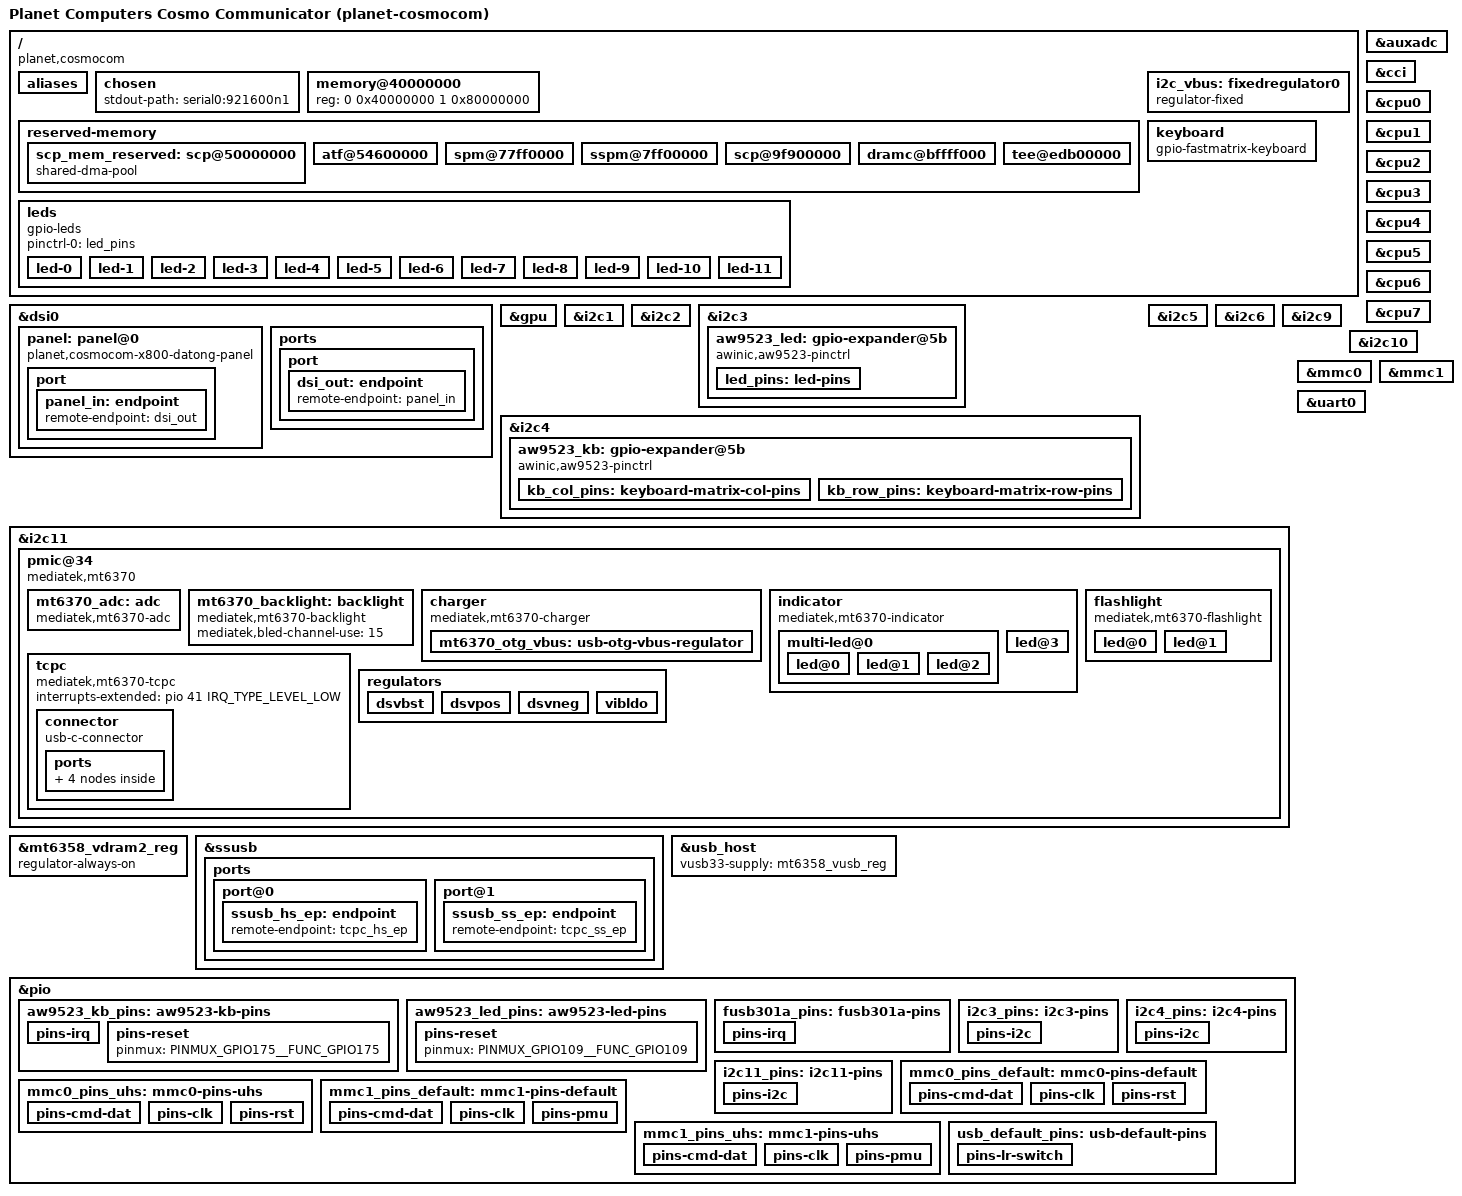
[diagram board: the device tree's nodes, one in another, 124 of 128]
// SPDX-License-Identifier: GPL-2.0-only
/dts-v1/;
#include <dt-bindings/gpio/gpio.h>
#include <dt-bindings/iio/adc/mediatek,mt6370_adc.h>
#include <dt-bindings/input/input.h>
#include <dt-bindings/interrupt-controller/irq.h>
#include <dt-bindings/leds/common.h>
#include <dt-bindings/usb/pd.h>
#include "mt6771.dtsi"
#include "mt6358.dtsi"

/ {
	model = "Planet Computers Cosmo Communicator (planet-cosmocom)";
	compatible = "planet,cosmocom", "mediatek,mt6771";
	chassis-type = "handset";

	aliases {
		serial0 = &uart0;
		mmc0 = &mmc0;
		mmc1 = &mmc1;
	};

	chosen {
		stdout-path = "serial0:921600n1";
	};

	memory@40000000 {
		device_type = "memory";
		reg = <0 0x40000000 1 0x80000000>;
	};

	reserved-memory {
		#address-cells = <2>;
		#size-cells = <2>;
		ranges;

		scp_mem_reserved: scp@50000000 {
                        compatible = "shared-dma-pool";
			reg = <0 0x50000000 0 0x140000>;
			no-map;
		};

		atf@54600000 {
			reg = <0 0x54600000 0 0x040000>;
			no-map;
		};

		spm@77ff0000 {
			reg = <0 0x77ff0000 0 0x010000>;
			no-map;
		};

		sspm@7ff00000 {
			reg = <0 0x7ff00000 0 0x0c0000>;
			no-map;
		};

                scp@9f900000 {
                        reg = <0 0x9f900000 0 0x600000>;
                        no-map;
                };

		dramc@bffff000 {
			reg = <0 0xbffff000 0 0x1000>;
			no-map;
		};

		tee@edb00000 {
			reg = <0 0xedb00000 0 0x02440000>;
			no-map;
		};
	};

	/*
	framebuffer@7df70000 {
		compatible = "simple-framebuffer";
		reg = <0 0x7df70000 0 0x1f90000>;
		format = "a8r8g8b8";
		width = <1080>;
		stride = <4352>;
		height = <2160>;
	};
	*/

	i2c_vbus: fixedregulator0 {
		compatible = "regulator-fixed";
		regulator-name = "i2c-vbus";
		regulator-min-microvolt = <1800000>;
		regulator-max-microvolt = <1800000>;
		regulator-boot-on;
	};

	leds {
		pinctrl-names = "default";
		pinctrl-0 = <&led_pins>;
		compatible = "gpio-leds";

		led-0 {
			gpios = <&aw9523_led 0 GPIO_ACTIVE_LOW>;
			function = LED_FUNCTION_CAPSLOCK;
			color = <LED_COLOR_ID_RED>;
		};

		led-1 {
			gpios = <&aw9523_led 1 GPIO_ACTIVE_LOW>;
			function = LED_FUNCTION_NUMLOCK;
			color = <LED_COLOR_ID_GREEN>;
		};

		led-2 {
			gpios = <&aw9523_led 2 GPIO_ACTIVE_LOW>;
			function = LED_FUNCTION_SCROLLLOCK;
			color = <LED_COLOR_ID_BLUE>;
		};

		led-3 {
			gpios = <&aw9523_led 3 GPIO_ACTIVE_LOW>;
			function = LED_FUNCTION_STATUS;
			color = <LED_COLOR_ID_RED>;
		};

		led-4 {
			gpios = <&aw9523_led 4 GPIO_ACTIVE_LOW>;
			function = LED_FUNCTION_STATUS;
			color = <LED_COLOR_ID_GREEN>;
		};

		led-5 {
			gpios = <&aw9523_led 5 GPIO_ACTIVE_LOW>;
			function = LED_FUNCTION_STATUS;
			color = <LED_COLOR_ID_BLUE>;
		};

		led-6 {
			gpios = <&aw9523_led 7 GPIO_ACTIVE_LOW>;
			function = LED_FUNCTION_INDICATOR;
			color = <LED_COLOR_ID_RED>;
		};

		led-7 {
			gpios = <&aw9523_led 8 GPIO_ACTIVE_LOW>;
			function = LED_FUNCTION_INDICATOR;
			color = <LED_COLOR_ID_GREEN>;
		};

		led-8 {
			gpios = <&aw9523_led 9 GPIO_ACTIVE_LOW>;
			function = LED_FUNCTION_INDICATOR;
			color = <LED_COLOR_ID_BLUE>;
		};

		led-9 {
			gpios = <&aw9523_led 11 GPIO_ACTIVE_LOW>;
			function = LED_FUNCTION_INDICATOR;
			color = <LED_COLOR_ID_RED>;
		};

		led-10 {
			gpios = <&aw9523_led 12 GPIO_ACTIVE_LOW>;
			function = LED_FUNCTION_INDICATOR;
			color = <LED_COLOR_ID_GREEN>;
		};

		led-11 {
			gpios = <&aw9523_led 13 GPIO_ACTIVE_LOW>;
			function = LED_FUNCTION_INDICATOR;
			color = <LED_COLOR_ID_BLUE>;
		};
	};

	keyboard {
		pinctrl-names = "default";
		pinctrl-0 = <&kb_col_pins>, <&kb_row_pins>;
		compatible = "gpio-fastmatrix-keyboard";
		autorescan-ms = <5>;
		debounce-delay-ms = <2>;
		col-scan-delay-us = <1000>;

		row-gpios = <&aw9523_kb 0 GPIO_ACTIVE_LOW>,
			    <&aw9523_kb 1 GPIO_ACTIVE_LOW>,
			    <&aw9523_kb 2 GPIO_ACTIVE_LOW>,
			    <&aw9523_kb 3 GPIO_ACTIVE_LOW>,
			    <&aw9523_kb 4 GPIO_ACTIVE_LOW>,
			    <&aw9523_kb 5 GPIO_ACTIVE_LOW>,
			    <&aw9523_kb 6 GPIO_ACTIVE_LOW>,
			    <&aw9523_kb 7 GPIO_ACTIVE_LOW>;

		col-gpios = <&aw9523_kb 8 GPIO_ACTIVE_LOW>,
			    <&aw9523_kb 9 GPIO_ACTIVE_LOW>,
			    <&aw9523_kb 10 GPIO_ACTIVE_LOW>,
			    <&aw9523_kb 11 GPIO_ACTIVE_LOW>,
			    <&aw9523_kb 12 GPIO_ACTIVE_LOW>,
			    <&aw9523_kb 13 GPIO_ACTIVE_LOW>,
			    <&aw9523_kb 14 GPIO_ACTIVE_LOW>;

		linux,keymap = <
			MATRIX_KEY(0, 0, KEY_1)
			MATRIX_KEY(1, 0, KEY_U)
			MATRIX_KEY(2, 0, KEY_S)
			MATRIX_KEY(3, 0, KEY_Z)
			MATRIX_KEY(4, 0, KEY_COMMA)
			MATRIX_KEY(5, 0, KEY_APOSTROPHE)
			MATRIX_KEY(6, 0, KEY_8)
			MATRIX_KEY(7, 0, KEY_J)

			MATRIX_KEY(0, 1, KEY_2)
			MATRIX_KEY(1, 1, KEY_W)
			MATRIX_KEY(2, 1, KEY_D)
			MATRIX_KEY(3, 1, KEY_C)
			MATRIX_KEY(4, 1, KEY_LEFTALT)
			MATRIX_KEY(5, 1, KEY_LEFT)
			MATRIX_KEY(6, 1, KEY_9)
			MATRIX_KEY(7, 1, KEY_K)

			MATRIX_KEY(0, 2, KEY_3)
			MATRIX_KEY(1, 2, KEY_Y)
			MATRIX_KEY(2, 2, KEY_TAB)
			MATRIX_KEY(3, 2, KEY_N)
			MATRIX_KEY(4, 2, KEY_M)
			MATRIX_KEY(5, 2, KEY_DOWN)
			MATRIX_KEY(6, 2, KEY_BACKSPACE)
			MATRIX_KEY(7, 2, KEY_I)

			MATRIX_KEY(0, 3, KEY_4)
			MATRIX_KEY(1, 3, KEY_T)
			MATRIX_KEY(2, 3, KEY_F)
			MATRIX_KEY(3, 3, KEY_X)
			MATRIX_KEY(4, 3, KEY_LEFTMETA)
			MATRIX_KEY(5, 3, KEY_RIGHTSHIFT)
			MATRIX_KEY(6, 3, KEY_P)

			MATRIX_KEY(0, 4, KEY_5)
			MATRIX_KEY(1, 4, KEY_E)
			MATRIX_KEY(2, 4, KEY_G)
			MATRIX_KEY(3, 4, KEY_V)
			MATRIX_KEY(4, 4, KEY_SPACE)
			MATRIX_KEY(5, 4, KEY_UP)
			MATRIX_KEY(6, 4, KEY_O)

			MATRIX_KEY(0, 5, KEY_6)
			MATRIX_KEY(1, 5, KEY_Q)
			MATRIX_KEY(2, 5, KEY_A)
			MATRIX_KEY(3, 5, KEY_B)
			MATRIX_KEY(4, 5, KEY_DOT)
			MATRIX_KEY(5, 5, KEY_RIGHT)
			MATRIX_KEY(6, 5, KEY_ENTER)

			MATRIX_KEY(0, 6, KEY_7)
			MATRIX_KEY(1, 6, KEY_R)
			MATRIX_KEY(2, 6, KEY_H)
			MATRIX_KEY(3, 6, KEY_LEFTSHIFT)
			MATRIX_KEY(4, 6, KEY_LEFTCTRL)
			MATRIX_KEY(5, 6, KEY_L)
			MATRIX_KEY(6, 6, KEY_0)
		>;
	};
};

&auxadc {
	status = "okay";
};

&cci {
	proc-supply = <&mt6358_vproc12_reg>;
	sram-supply = <&mt6358_vsram_proc12_reg>;
};

&cpu0 {
	proc-supply = <&mt6358_vproc12_reg>;
	sram-supply = <&mt6358_vsram_proc12_reg>;
};

&cpu1 {
	proc-supply = <&mt6358_vproc12_reg>;
	sram-supply = <&mt6358_vsram_proc12_reg>;
};

&cpu2 {
	proc-supply = <&mt6358_vproc12_reg>;
	sram-supply = <&mt6358_vsram_proc12_reg>;
};

&cpu3 {
	proc-supply = <&mt6358_vproc12_reg>;
	sram-supply = <&mt6358_vsram_proc12_reg>;
};

&cpu4 {
	proc-supply = <&mt6358_vproc11_reg>;
	sram-supply = <&mt6358_vsram_proc11_reg>;
};

&cpu5 {
	proc-supply = <&mt6358_vproc11_reg>;
	sram-supply = <&mt6358_vsram_proc11_reg>;
};

&cpu6 {
	proc-supply = <&mt6358_vproc11_reg>;
	sram-supply = <&mt6358_vsram_proc11_reg>;
};

&cpu7 {
	proc-supply = <&mt6358_vproc11_reg>;
	sram-supply = <&mt6358_vsram_proc11_reg>;
};

&dsi0 {
	status = "okay";
	#address-cells = <1>;
	#size-cells = <0>;
	panel: panel@0 {
		compatible = "planet,cosmocom-x800-datong-panel";
		reg = <0>;
		backlight = <&mt6370_backlight>;
		rotation = <270>;
		port {
			panel_in: endpoint {
				remote-endpoint = <&dsi_out>;
			};
		};
	};

	ports {
		port {
			dsi_out: endpoint {
				remote-endpoint = <&panel_in>;
			};
		};
	};
};

&gpu {
	mali-supply = <&mt6358_vgpu_reg>;
	sram-supply = <&mt6358_vsram_gpu_reg>;
};

&i2c1 {
	status = "okay";
};

&i2c2 {
	status = "okay";
};

&i2c3 {
	#address-cells = <1>;
	#size-cells = <0>;
	pinctrl-names = "default";
	pinctrl-0 = <&i2c3_pins>;
	/* hack to get i2c to probe with vbus-supply in tcpc */
	vbus-supply = <&i2c_vbus>;
	clock-frequency = <400000>;
	status = "okay";

#if 0
	tcpc@25 {
		pinctrl-names = "default";
		pinctrl-0 = <&fusb301a_pins>;
		compatible = "fcs,fusb301";
		reg = <0x25>;
		interrupt-parent = <&pio>;
		interrupts = <166 IRQ_TYPE_EDGE_BOTH>;

		connector {
			compatible = "usb-c-connector";
			label = "USB-C";
			vbus-supply = <&mt6370_otg_vbus>;
			data-role = "dual";
			power-role = "dual";
			try-power-role = "sink";
			typec-power-opmode = "default";
			pd-disable;

			ports {
				#address-cells = <1>;
				#size-cells = <0>;

				port@0 {
					tcpc_hs_ep: endpoint {
						remote-endpoint = <&ssusb_hs_ep>;
					};
				};

				port@1 {
					tcpc_ss_ep: endpoint {
						remote-endpoint = <&ssusb_ss_ep>;
					};
				};
			};
		};
	};
#endif

	aw9523_led: gpio-expander@5b {
		pinctrl-names = "default";
		pinctrl-0 = <&aw9523_led_pins>;
		compatible = "awinic,aw9523-pinctrl";
		reg = <0x5b>;
		gpio-controller;
		#gpio-cells = <2>;
		gpio-ranges = <&aw9523_led 0 0 16>;
		interrupt-controller;
		#interrupt-cells = <2>;
		reset-gpios = <&pio 109 GPIO_ACTIVE_HIGH>;

		led_pins: led-pins {
			pins = "gpio0", "gpio1", "gpio2",
			       "gpio3", "gpio4", "gpio5",
			       "gpio6", "gpio7", "gpio8",
			       "gpio9", "gpio10", "gpio11",
			       "gpio12", "gpio13", "gpio14";
			function = "gpio";
			input-disable;
			drive-push-pull;
			output-high;
		};
	};
};

&i2c4 {
	/* use channel 1 instead of 0 */
	reg = <0 0x11008100 0 0xf00>,
	      <0 0x11000100 0 0x80>;
	#address-cells = <1>;
	#size-cells = <0>;
	pinctrl-names = "default";
	pinctrl-0 = <&i2c4_pins>;
	clock-frequency = <400000>;
	status = "okay";

	aw9523_kb: gpio-expander@5b {
		pinctrl-names = "default";
		pinctrl-0 = <&aw9523_kb_pins>;
		compatible = "awinic,aw9523-pinctrl";
		reg = <0x5b>;
		interrupt-parent = <&pio>;
		interrupts = <12 IRQ_TYPE_LEVEL_LOW>;
		gpio-controller;
		#gpio-cells = <2>;
		gpio-ranges = <&aw9523_kb 0 0 16>;
		interrupt-controller;
		#interrupt-cells = <2>;
		reset-gpios = <&pio 175 GPIO_ACTIVE_HIGH>;

		kb_col_pins: keyboard-matrix-col-pins {
			pins = "gpio8", "gpio9", "gpio10", "gpio11",
			       "gpio12", "gpio13", "gpio14";
			function = "gpio";
			input-disable;
			output-low;
		};

		kb_row_pins: keyboard-matrix-row-pins {
			pins = "gpio0", "gpio1", "gpio2", "gpio3",
			       "gpio4", "gpio5", "gpio6", "gpio7";
			function = "gpio";
			bias-pull-up;
			drive-open-drain;
			input-enable;
		};
	};
};

&i2c5 {
	status = "okay";
};

&i2c6 {
	status = "okay";
};

&i2c9 {
	status = "okay";
};

&i2c10 {
	status = "okay";
};

&i2c11 {
	#address-cells = <1>;
	#size-cells = <0>;
	pinctrl-names = "default";
	pinctrl-0 = <&i2c11_pins>;
	/* hack to get i2c to probe with vbus-supply in tcpc */
	vbus-supply = <&i2c_vbus>;
	clock-frequency = <3400000>;
	status = "okay";

	pmic@34 {
		compatible = "mediatek,mt6370";
		reg = <0x34>;
		wakeup-source;
		interrupts-extended = <&pio 10 IRQ_TYPE_LEVEL_LOW>;
		interrupt-controller;
		#interrupt-cells = <1>;

		mt6370_adc: adc {
			compatible = "mediatek,mt6370-adc";
			#io-channel-cells = <1>;
		};

		mt6370_backlight: backlight {
			compatible = "mediatek,mt6370-backlight";
			mediatek,bled-channel-use = /bits/ 8 <15>;
		};

		charger {
			compatible = "mediatek,mt6370-charger";
			interrupts = <68>, <48>, <6>;
			interrupt-names = "uvp_d_evt", "attach_i", "mivr";
			io-channels = <&mt6370_adc MT6370_CHAN_IBUS>;

			mt6370_otg_vbus: usb-otg-vbus-regulator {
				regulator-name = "mt6370-usb-otg-vbus";
				regulator-min-microvolt = <4350000>;
				regulator-max-microvolt = <5800000>;
				regulator-min-microamp = <500000>;
				regulator-max-microamp = <3000000>;
			};
		};

		indicator {
			compatible = "mediatek,mt6370-indicator";
			#address-cells = <1>;
			#size-cells = <0>;

			multi-led@0 {
				reg = <0>;
				function = LED_FUNCTION_INDICATOR;
				color = <LED_COLOR_ID_RGB>;
				led-max-microamp = <24000>;
				#address-cells = <1>;
				#size-cells = <0>;
				led@0 {
					reg = <0>;
					color = <LED_COLOR_ID_RED>;
				};
				led@1 {
					reg = <1>;
					color = <LED_COLOR_ID_GREEN>;
				};
				led@2 {
					reg = <2>;
					color = <LED_COLOR_ID_BLUE>;
				};
			};
			led@3 {
				reg = <3>;
				function = LED_FUNCTION_INDICATOR;
				color = <LED_COLOR_ID_WHITE>;
				led-max-microamp = <6000>;
			};
		};

		flashlight {
			compatible = "mediatek,mt6370-flashlight";
			#address-cells = <1>;
			#size-cells = <0>;
			led@0 {
				reg = <0>;
				led-sources = <0>;
				function = LED_FUNCTION_FLASH;
				color = <LED_COLOR_ID_WHITE>;
				function-enumerator = <1>;
				led-max-microamp = <300000>;
				flash-max-microamp = <1200000>;
				flash-max-timeout-us = <2400000>;
			};
			led@1 {
				reg = <1>;
				led-sources = <1>;
				function = LED_FUNCTION_FLASH;
				color = <LED_COLOR_ID_WHITE>;
				function-enumerator = <2>;
				led-max-microamp = <200000>;
				flash-max-microamp = <1000000>;
				flash-max-timeout-us = <1200000>;
			};
		};

		tcpc {
			compatible = "mediatek,mt6370-tcpc";
			interrupts-extended = <&pio 41 IRQ_TYPE_LEVEL_LOW>;

			connector {
				compatible = "usb-c-connector";
				label = "USB-C";
				vbus-supply = <&mt6370_otg_vbus>;
				data-role = "dual";
				power-role = "dual";
				try-power-role = "sink";
				source-pdos = <PDO_FIXED(5000, 500, PDO_FIXED_DUAL_ROLE | PDO_FIXED_DATA_SWAP)>;
				sink-pdos = <PDO_FIXED(5000, 2000, PDO_FIXED_DUAL_ROLE | PDO_FIXED_DATA_SWAP)>;
				op-sink-microwatt = <10000000>;

				ports {
					#address-cells = <1>;
					#size-cells = <0>;

					port@0 {
						tcpc_hs_ep: endpoint {
							remote-endpoint = <&ssusb_hs_ep>;
						};
					};

					port@1 {
						tcpc_ss_ep: endpoint {
							remote-endpoint = <&ssusb_ss_ep>;
						};
					};
				};
			};
		};

		regulators {
			dsvbst {
				regulator-name = "mt6370-dsv-vbst";
				regulator-min-microvolt = <4000000>;
				regulator-max-microvolt = <6200000>;
			};
			dsvpos {
				regulator-name = "mt6370-dsv-vpos";
				regulator-min-microvolt = <4000000>;
				regulator-max-microvolt = <6000000>;
				regulator-always-on;
			};
			dsvneg {
				regulator-name = "mt6370-dsv-vneg";
				regulator-min-microvolt = <4000000>;
				regulator-max-microvolt = <6000000>;
				regulator-always-on;
			};
			vibldo {
				regulator-name = "mt6370-vib-ldo";
				regulator-min-microvolt = <1600000>;
				regulator-max-microvolt = <4000000>;
			};
		};
	};
};

&mmc0 {
	status = "okay";
	pinctrl-names = "default", "state_uhs";
	pinctrl-0 = <&mmc0_pins_default>;
	pinctrl-1 = <&mmc0_pins_uhs>;
	bus-width = <8>;
	max-frequency = <200000000>;
	cap-mmc-highspeed;
	mmc-ddr-1_8v;
	mmc-hs200-1_8v;
	mmc-hs400-1_8v;
	cap-mmc-hw-reset;
	no-sdio;
	no-sd;
	hs400-ds-delay = <0x12814>;
	vmmc-supply = <&mt6358_vemc_reg>;
	vqmmc-supply = <&mt6358_vio18_reg>;
	assigned-clocks = <&topckgen CLK_TOP_MUX_MSDC50_0>;
	assigned-clock-parents = <&topckgen CLK_TOP_MSDCPLL_CK>;
	non-removable;
};

&mmc1 {
	status = "okay";
	pinctrl-names = "default", "state_uhs";
	pinctrl-0 = <&mmc1_pins_default>;
	pinctrl-1 = <&mmc1_pins_uhs>;
	bus-width = <4>;
	max-frequency = <200000000>;
	cap-sd-highspeed;
	sd-uhs-sdr12;
	sd-uhs-sdr25;
	sd-uhs-sdr50;
	sd-uhs-sdr104;
	sd-uhs-ddr50;
	vmmc-supply = <&mt6358_vmch_reg>;
	vqmmc-supply = <&mt6358_vmc_reg>;
	assigned-clocks = <&topckgen CLK_TOP_MUX_MSDC30_1>;
	assigned-clock-parents = <&topckgen CLK_TOP_MSDCPLL_D2>;
};

&mt6358_vdram2_reg {
	regulator-always-on;
};

&ssusb {
	pinctrl-names = "default";
	pinctrl-0 = <&usb_default_pins>;
	status = "okay";
	mediatek,u3p-dis-msk = <1>;
	dr_mode = "otg";
	usb-role-switch;
	role-switch-default-mode = "peripheral";
	vusb33-supply = <&mt6358_vusb_reg>;
	wakeup-source;

	ports {
		#address-cells = <1>;
		#size-cells = <0>;

		port@0 {
			ssusb_hs_ep: endpoint {
				remote-endpoint = <&tcpc_hs_ep>;
			};
		};

		port@1 {
			ssusb_ss_ep: endpoint {
				remote-endpoint = <&tcpc_ss_ep>;
			};
		};
	};
};

&uart0 {
	status = "okay";
};

&usb_host {
	vusb33-supply = <&mt6358_vusb_reg>;
	status = "okay";
};

&pio {
	aw9523_kb_pins: aw9523-kb-pins {
		pins-irq {
			pinmux = <PINMUX_GPIO12__FUNC_GPIO12>;
			input-enable;
			bias-pull-up;
		};
		pins-reset {
			pinmux = <PINMUX_GPIO175__FUNC_GPIO175>;
		};
	};

	aw9523_led_pins: aw9523-led-pins {
		pins-reset {
			pinmux = <PINMUX_GPIO109__FUNC_GPIO109>;
		};
	};

	fusb301a_pins: fusb301a-pins {
		pins-irq {
			pinmux = <PINMUX_GPIO166__FUNC_GPIO166>;
			input-enable;
			bias-pull-up;
		};
	};

	i2c3_pins: i2c3-pins {
		pins-i2c {
			pinmux = <PINMUX_GPIO50__FUNC_SCL3>,
				 <PINMUX_GPIO51__FUNC_SDA3>;
		};
	};

	i2c4_pins: i2c4-pins {
		pins-i2c {
			pinmux = <PINMUX_GPIO105__FUNC_SCL4>,
				 <PINMUX_GPIO106__FUNC_SDA4>;
		};
	};

	i2c11_pins: i2c11-pins {
		pins-i2c {
			pinmux = <PINMUX_GPIO48__FUNC_SCL5>,
				 <PINMUX_GPIO49__FUNC_SDA5>;
		};
	};

	mmc0_pins_default: mmc0-pins-default {
		pins-cmd-dat {
			pinmux = <PINMUX_GPIO123__FUNC_MSDC0_DAT0>,
				 <PINMUX_GPIO128__FUNC_MSDC0_DAT1>,
				 <PINMUX_GPIO125__FUNC_MSDC0_DAT2>,
				 <PINMUX_GPIO132__FUNC_MSDC0_DAT3>,
				 <PINMUX_GPIO126__FUNC_MSDC0_DAT4>,
				 <PINMUX_GPIO129__FUNC_MSDC0_DAT5>,
				 <PINMUX_GPIO127__FUNC_MSDC0_DAT6>,
				 <PINMUX_GPIO130__FUNC_MSDC0_DAT7>,
				 <PINMUX_GPIO122__FUNC_MSDC0_CMD>;
			input-enable;
			drive-strength = <MTK_DRIVE_14mA>;
			mediatek,pull-up-adv = <01>;
		};

		pins-clk {
			pinmux = <PINMUX_GPIO124__FUNC_MSDC0_CLK>;
			drive-strength = <MTK_DRIVE_14mA>;
			mediatek,pull-down-adv = <10>;
		};

		pins-rst {
			pinmux = <PINMUX_GPIO133__FUNC_MSDC0_RSTB>;
			drive-strength = <MTK_DRIVE_14mA>;
			mediatek,pull-down-adv = <01>;
		};
	};

	mmc0_pins_uhs: mmc0-pins-uhs {
		pins-cmd-dat {
			pinmux = <PINMUX_GPIO123__FUNC_MSDC0_DAT0>,
				 <PINMUX_GPIO128__FUNC_MSDC0_DAT1>,
				 <PINMUX_GPIO125__FUNC_MSDC0_DAT2>,
				 <PINMUX_GPIO132__FUNC_MSDC0_DAT3>,
				 <PINMUX_GPIO126__FUNC_MSDC0_DAT4>,
				 <PINMUX_GPIO129__FUNC_MSDC0_DAT5>,
				 <PINMUX_GPIO127__FUNC_MSDC0_DAT6>,
				 <PINMUX_GPIO130__FUNC_MSDC0_DAT7>,
				 <PINMUX_GPIO122__FUNC_MSDC0_CMD>;
			input-enable;
			drive-strength = <MTK_DRIVE_14mA>;
			mediatek,pull-up-adv = <01>;
		};

		pins-clk {
			pinmux = <PINMUX_GPIO124__FUNC_MSDC0_CLK>;
			drive-strength = <MTK_DRIVE_14mA>;
			mediatek,pull-down-adv = <10>;
		};

		pins-rst {
			pinmux = <PINMUX_GPIO133__FUNC_MSDC0_RSTB>;
			drive-strength = <MTK_DRIVE_14mA>;
			mediatek,pull-down-adv = <01>;
		};
	};

	mmc1_pins_default: mmc1-pins-default {
		pins-cmd-dat {
			pinmux = <PINMUX_GPIO31__FUNC_MSDC1_CMD>,
				 <PINMUX_GPIO32__FUNC_MSDC1_DAT0>,
				 <PINMUX_GPIO34__FUNC_MSDC1_DAT1>,
				 <PINMUX_GPIO33__FUNC_MSDC1_DAT2>,
				 <PINMUX_GPIO30__FUNC_MSDC1_DAT3>;
			input-enable;
			drive-strength = <MTK_DRIVE_10mA>;
			mediatek,pull-up-adv = <10>;
		};

		pins-clk {
			pinmux = <PINMUX_GPIO29__FUNC_MSDC1_CLK>;
			input-enable;
			drive-strength = <MTK_DRIVE_10mA>;
			mediatek,pull-down-adv = <10>;
		};

		pins-pmu {
			pinmux = <PINMUX_GPIO178__FUNC_GPIO178>;
			drive-strength = <MTK_DRIVE_10mA>;
			output-high;
		};
	};

	mmc1_pins_uhs: mmc1-pins-uhs {
		pins-cmd-dat {
			pinmux = <PINMUX_GPIO31__FUNC_MSDC1_CMD>,
				 <PINMUX_GPIO32__FUNC_MSDC1_DAT0>,
				 <PINMUX_GPIO34__FUNC_MSDC1_DAT1>,
				 <PINMUX_GPIO33__FUNC_MSDC1_DAT2>,
				 <PINMUX_GPIO30__FUNC_MSDC1_DAT3>;
			input-enable;
			drive-strength = <MTK_DRIVE_10mA>;
			mediatek,pull-up-adv = <10>;
		};

		pins-clk {
			pinmux = <PINMUX_GPIO29__FUNC_MSDC1_CLK>;
			input-enable;
			drive-strength = <MTK_DRIVE_10mA>;
			mediatek,pull-down-adv = <10>;
		};

		pins-pmu {
			pinmux = <PINMUX_GPIO178__FUNC_GPIO178>;
			drive-strength = <MTK_DRIVE_10mA>;
			output-high;
		};
	};

	usb_default_pins: usb-default-pins {
		pins-lr-switch {
			pinmux = <PINMUX_GPIO79__FUNC_GPIO79>;
			output-low; /* left USB port */
		};
	};
};
